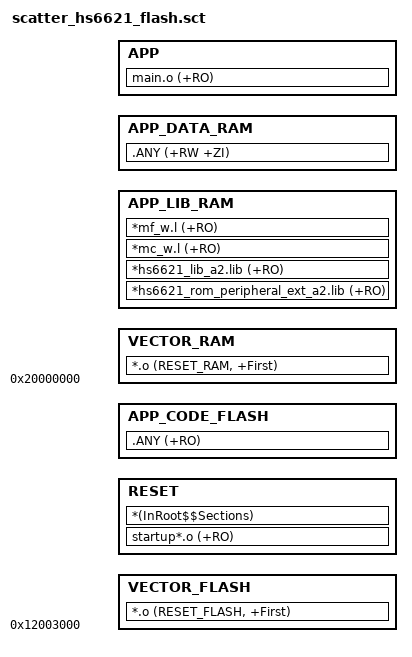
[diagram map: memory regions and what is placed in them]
#! armcc -E
; ***************************************************************
; *** Scatter-Loading Description File generated by Huntersun ***
; ***************************************************************

FLASH_LOAD 0x12003000 0x00800000
{
    VECTOR_FLASH 0x12003000
    {
        *.o (RESET_FLASH, +First)
    }

    RESET +0
    {
        startup*.o (+RO)
        *(InRoot$$Sections)
    }

    APP_CODE_FLASH +0
    {
        .ANY (+RO)
    }

    VECTOR_RAM 0x20000000
    {
        *.o (RESET_RAM, +First)
    }

    APP_LIB_RAM +0
    {
        *hs6621_rom_peripheral_ext_a2.lib (+RO)
        *hs6621_lib_a2.lib (+RO)
        *mc_w.l (+RO)
        *mf_w.l (+RO)
    }

    APP_DATA_RAM +0
    {
        .ANY (+RW +ZI)
    }

    APP +0
    {
        main.o (+RO)
    }
}

ScatterAssert(ImageLimit(RESET) < (0x12003000+0x00002000))
ScatterAssert(ImageLimit(APP)   < (0x20000000+0x0003e988))

